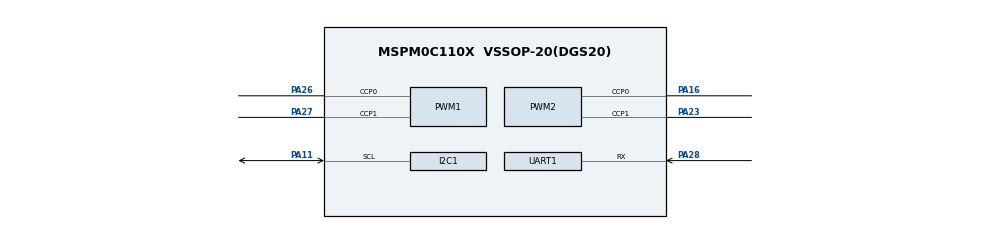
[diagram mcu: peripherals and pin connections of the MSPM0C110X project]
/**
 * @cliArgs --device "MSPM0C110X" --part "Default" --package "VSSOP-20(DGS20)" --product "mspm0_sdk@2.10.00.04"
 * @versions {"tool":"1.26.2+4477"}
 */

/**
 * Import the modules used in this configuration.
 */
const Board  = scripting.addModule("/ti/driverlib/Board");
const GPIO   = scripting.addModule("/ti/driverlib/GPIO", {}, false);
const GPIO1  = GPIO.addInstance();
const I2C    = scripting.addModule("/ti/driverlib/I2C", {}, false);
const I2C1   = I2C.addInstance();
const PWM    = scripting.addModule("/ti/driverlib/PWM", {}, false);
const PWM1   = PWM.addInstance();
const PWM2   = PWM.addInstance();
const SYSCTL = scripting.addModule("/ti/driverlib/SYSCTL");
const UART   = scripting.addModule("/ti/driverlib/UART", {}, false);
const UART1  = UART.addInstance();

/**
 * Write custom configuration values to the imported modules.
 */

GPIO1.$name                         = "GPIO_GRP_0";
GPIO1.port                          = "PORTA";
GPIO1.portSegment                   = "Lower";
GPIO1.associatedPins[0].$name       = "PIN_0";
GPIO1.associatedPins[0].direction   = "INPUT";
GPIO1.associatedPins[0].interruptEn = true;
GPIO1.associatedPins[0].polarity    = "RISE";
GPIO1.associatedPins[0].pubChanID   = 1;

I2C1.$name                           = "I2C_0";
I2C1.basicEnableController           = true;
I2C1.basicControllerBusSpeed         = 400000;
I2C1.basicControllerStandardBusSpeed = "Fast";
I2C1.advControllerTXFIFOTRIG         = "BYTES_3";
I2C1.peripheral.sclPin.$assign       = "PA11";
I2C1.sdaPinConfig.$name              = "ti_driverlib_gpio_GPIOPinGeneric0";
I2C1.sdaPinConfig.enableConfig       = true;
I2C1.sclPinConfig.$name              = "ti_driverlib_gpio_GPIOPinGeneric1";

PWM1.$name                      = "PWM_0";
PWM1.timerStartTimer            = true;
PWM1.timerCount                 = 256;
PWM1.peripheral.ccp0Pin.$assign = "PA26";
PWM1.peripheral.ccp1Pin.$assign = "PA27";
PWM1.PWM_CHANNEL_0.$name        = "ti_driverlib_pwm_PWMTimerCC0";
PWM1.PWM_CHANNEL_1.$name        = "ti_driverlib_pwm_PWMTimerCC1";
PWM1.ccp0PinConfig.$name        = "ti_driverlib_gpio_GPIOPinGeneric4";
PWM1.ccp1PinConfig.$name        = "ti_driverlib_gpio_GPIOPinGeneric5";

PWM2.$name                      = "PWM_1";
PWM2.timerCount                 = 256;
PWM2.peripheral.ccp0Pin.$assign = "PA16";
PWM2.peripheral.ccp1Pin.$assign = "PA23";
PWM2.PWM_CHANNEL_0.$name        = "ti_driverlib_pwm_PWMTimerCC2";
PWM2.PWM_CHANNEL_1.$name        = "ti_driverlib_pwm_PWMTimerCC3";
PWM2.ccp0PinConfig.$name        = "ti_driverlib_gpio_GPIOPinGeneric6";
PWM2.ccp1PinConfig.$name        = "ti_driverlib_gpio_GPIOPinGeneric7";

SYSCTL.disableNRSTPin = true;

UART1.$name                        = "UART_0";
UART1.enableFIFO                   = true;
UART1.enabledInterrupts            = ["RX"];
UART1.rxFifoThreshold              = "DL_UART_RX_FIFO_LEVEL_ONE_ENTRY";
UART1.targetBaudRate               = 416666;
UART1.ovsRate                      = "8";
UART1.peripheral.rxPin.$assign     = "PA28";
UART1.txPinConfig.$name            = "ti_driverlib_gpio_GPIOPinGeneric2";
UART1.rxPinConfig.$name            = "ti_driverlib_gpio_GPIOPinGeneric3";
UART1.rxPinConfig.enableConfig     = true;
UART1.rxPinConfig.internalResistor = "PULL_DOWN";

/**
 * Pinmux solution for unlocked pins/peripherals. This ensures that minor changes to the automatic solver in a future
 * version of the tool will not impact the pinmux you originally saw.  These lines can be completely deleted in order to
 * re-solve from scratch.
 */
Board.peripheral.$suggestSolution            = "DEBUGSS";
Board.peripheral.swclkPin.$suggestSolution   = "PA20";
Board.peripheral.swdioPin.$suggestSolution   = "PA19";
GPIO1.associatedPins[0].pin.$suggestSolution = "PA1/NRST";
I2C1.peripheral.$suggestSolution             = "I2C0";
I2C1.peripheral.sdaPin.$suggestSolution      = "PA0";
PWM1.peripheral.$suggestSolution             = "TIMG8";
PWM2.peripheral.$suggestSolution             = "TIMG14";
SYSCTL.peripheral.$suggestSolution           = "SYSCTL";
UART1.peripheral.$suggestSolution            = "UART0";
UART1.peripheral.txPin.$suggestSolution      = "PA17";
